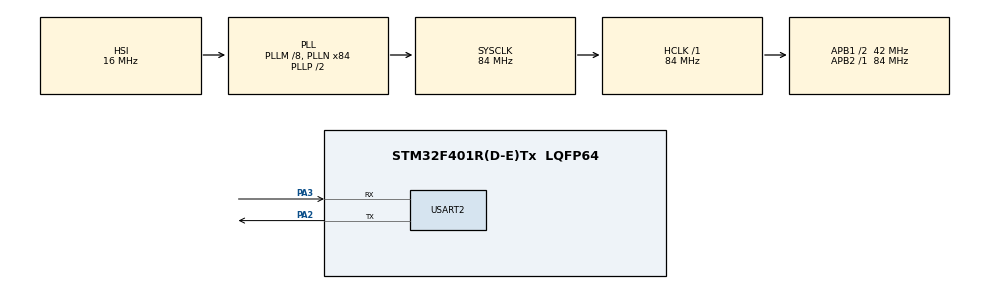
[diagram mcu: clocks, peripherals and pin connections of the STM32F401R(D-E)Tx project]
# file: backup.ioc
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Mcu.Family=STM32F4
Mcu.Name=STM32F401R(D-E)Tx
Mcu.Package=LQFP64
NVIC.PriorityGroup=NVIC_PRIORITYGROUP_4
NVIC.TIM5_IRQn=true\:15\:0\:false\:false\:true\:false\:true\:true
NVIC.TimeBase=TIM5_IRQn
NVIC.TimeBaseIP=TIM5
PA13.Mode=Serial_Wire
PA13.Signal=SYS_JTMS-SWDIO
PA14.Mode=Serial_Wire
PA14.Signal=SYS_JTCK-SWCLK
PA2.Mode=Asynchronous
PA2.Signal=USART2_TX
PA3.Mode=Asynchronous
PA3.Signal=USART2_RX
PH0\ -\ OSC_IN.Mode=HSE-External-Oscillator
PH0\ -\ OSC_IN.Signal=RCC_OSC_IN
PH1\ -\ OSC_OUT.Mode=HSE-External-Oscillator
PH1\ -\ OSC_OUT.Signal=RCC_OSC_OUT
ProjectManager.HeapSize=0x200
ProjectManager.StackSize=0x400
ProjectManager.TargetToolchain=Makefile
RCC.48MHZClocksFreq_Value=42000000
RCC.AHBFreq_Value=84000000
RCC.APB1CLKDivider=RCC_HCLK_DIV2
RCC.APB1Freq_Value=42000000
RCC.APB1TimFreq_Value=84000000
RCC.APB2Freq_Value=84000000
RCC.APB2TimFreq_Value=84000000
RCC.CortexFreq_Value=84000000
RCC.HCLKFreq_Value=84000000
RCC.HSE_VALUE=25000000
RCC.HSI_VALUE=16000000
RCC.LSE_VALUE=32768
RCC.PLLM=8
RCC.PLLN=84
RCC.SYSCLKFreq_VALUE=84000000
RCC.SYSCLKSource=RCC_SYSCLKSOURCE_PLLCLK
RCC.VCOOutputFreq_Value=168000000
USART2.VirtualMode=VM_ASYNC
VP_SYS_VS_tim5.Mode=TIM5
board=custom

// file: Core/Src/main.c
/* USER CODE BEGIN Header */
/**
  ******************************************************************************
  * @file           : main.c
  * @brief          : Main program body
  ******************************************************************************
  * @attention
  *
  * Copyright (c) 2024 STMicroelectronics.
  * All rights reserved.
  *
  * This software is licensed under terms that can be found in the LICENSE file
  * in the root directory of this software component.
  * If no LICENSE file comes with this software, it is provided AS-IS.
  *
  ******************************************************************************
  */
/* USER CODE END Header */
#include "main.h"
#include "usart.h"
#include "gpio.h"

/* USER CODE BEGIN Includes */
#include "FreeRTOS.h"
#include "task.h"
#include <string.h>

/* USER CODE END Includes */

void SystemClock_Config(void);
/* USER CODE BEGIN PFP */
void task2Handler(void *pvParameters);
void task1Handler(void *pvParameters);
/* USER CODE END PFP */

int main(void)
{
  /* USER CODE BEGIN 1 */
  TaskHandle_t task1Handle;
  TaskHandle_t task2Handle;
  BaseType_t status;

  /* USER CODE END 1 */

  /* MCU Configuration--------------------------------------------------------*/

  /* Reset of all peripherals, Initializes the Flash interface and the Systick. */
  HAL_Init();

  /* Configure the system clock */
  SystemClock_Config();

  /* Initialize all configured peripherals */
  MX_GPIO_Init();
  MX_USART2_UART_Init();
  /* USER CODE BEGIN 2 */
  status = xTaskCreate( task1Handler,
                        "Task",
                        1000,
                        "Hello world from task 1 \r\n",
                        2,
                        &task1Handle );

  configASSERT( status == pdPASS );

  status = xTaskCreate( task2Handler,
                        "Task",
                        1000,
                        "Hello world from task 2 \r\n",
                        1,
                        &task2Handle );

  configASSERT( status == pdPASS );

  /* start freeRTOS scheduler */
  vTaskStartScheduler();
  /* USER CODE END 2 */

  /* Infinite loop */
  while (1)
  {

  }
}

/* USER CODE BEGIN 4 */
void task1Handler(void *pvParameters)
{
  char *pcTaskName;
  pcTaskName = (char *) pvParameters;

  while(1)
  {
    HAL_UART_Transmit(&huart2, (uint8_t *)pcTaskName, strlen(pcTaskName), HAL_MAX_DELAY);
    vTaskDelay(1000);
  }
}

void task2Handler(void *pvParameters)
{
  char *pcTaskName;
  pcTaskName = (char *) pvParameters;

  while(1)
  {
    HAL_UART_Transmit(&huart2, (uint8_t *)pcTaskName, strlen(pcTaskName), HAL_MAX_DELAY);
    vTaskDelay(500);
  }
}

/**
  * @brief System Clock Configuration
  * @retval None
  */
void SystemClock_Config(void)
{
  RCC_OscInitTypeDef RCC_OscInitStruct = {0};
  RCC_ClkInitTypeDef RCC_ClkInitStruct = {0};

  /** Configure the main internal regulator output voltage
  */
  __HAL_RCC_PWR_CLK_ENABLE();
  __HAL_PWR_VOLTAGESCALING_CONFIG(PWR_REGULATOR_VOLTAGE_SCALE2);

  /** Initializes the RCC Oscillators according to the specified parameters
  * in the RCC_OscInitTypeDef structure.
  */
  RCC_OscInitStruct.OscillatorType = RCC_OSCILLATORTYPE_HSI;
  RCC_OscInitStruct.HSIState = RCC_HSI_ON;
  RCC_OscInitStruct.HSICalibrationValue = RCC_HSICALIBRATION_DEFAULT;
  RCC_OscInitStruct.PLL.PLLState = RCC_PLL_ON;
  RCC_OscInitStruct.PLL.PLLSource = RCC_PLLSOURCE_HSI;
  RCC_OscInitStruct.PLL.PLLM = 8;
  RCC_OscInitStruct.PLL.PLLN = 84;
  RCC_OscInitStruct.PLL.PLLP = RCC_PLLP_DIV2;
  RCC_OscInitStruct.PLL.PLLQ = 4;
  if (HAL_RCC_OscConfig(&RCC_OscInitStruct) != HAL_OK)
  {
    Error_Handler();
  }

  /** Initializes the CPU, AHB and APB buses clocks
  */
  RCC_ClkInitStruct.ClockType = RCC_CLOCKTYPE_HCLK|RCC_CLOCKTYPE_SYSCLK
                              |RCC_CLOCKTYPE_PCLK1|RCC_CLOCKTYPE_PCLK2;
  RCC_ClkInitStruct.SYSCLKSource = RCC_SYSCLKSOURCE_PLLCLK;
  RCC_ClkInitStruct.AHBCLKDivider = RCC_SYSCLK_DIV1;
  RCC_ClkInitStruct.APB1CLKDivider = RCC_HCLK_DIV2;
  RCC_ClkInitStruct.APB2CLKDivider = RCC_HCLK_DIV1;

  if (HAL_RCC_ClockConfig(&RCC_ClkInitStruct, FLASH_LATENCY_2) != HAL_OK)
  {
    Error_Handler();
  }
}

/* USER CODE BEGIN 4 */

/* USER CODE END 4 */

void HAL_TIM_PeriodElapsedCallback(TIM_HandleTypeDef *htim)
{
  if (htim->Instance == TIM5) {
    HAL_IncTick();
  }
}

void Error_Handler(void)
{
  __disable_irq();
  while (1)
  {
  }
}
